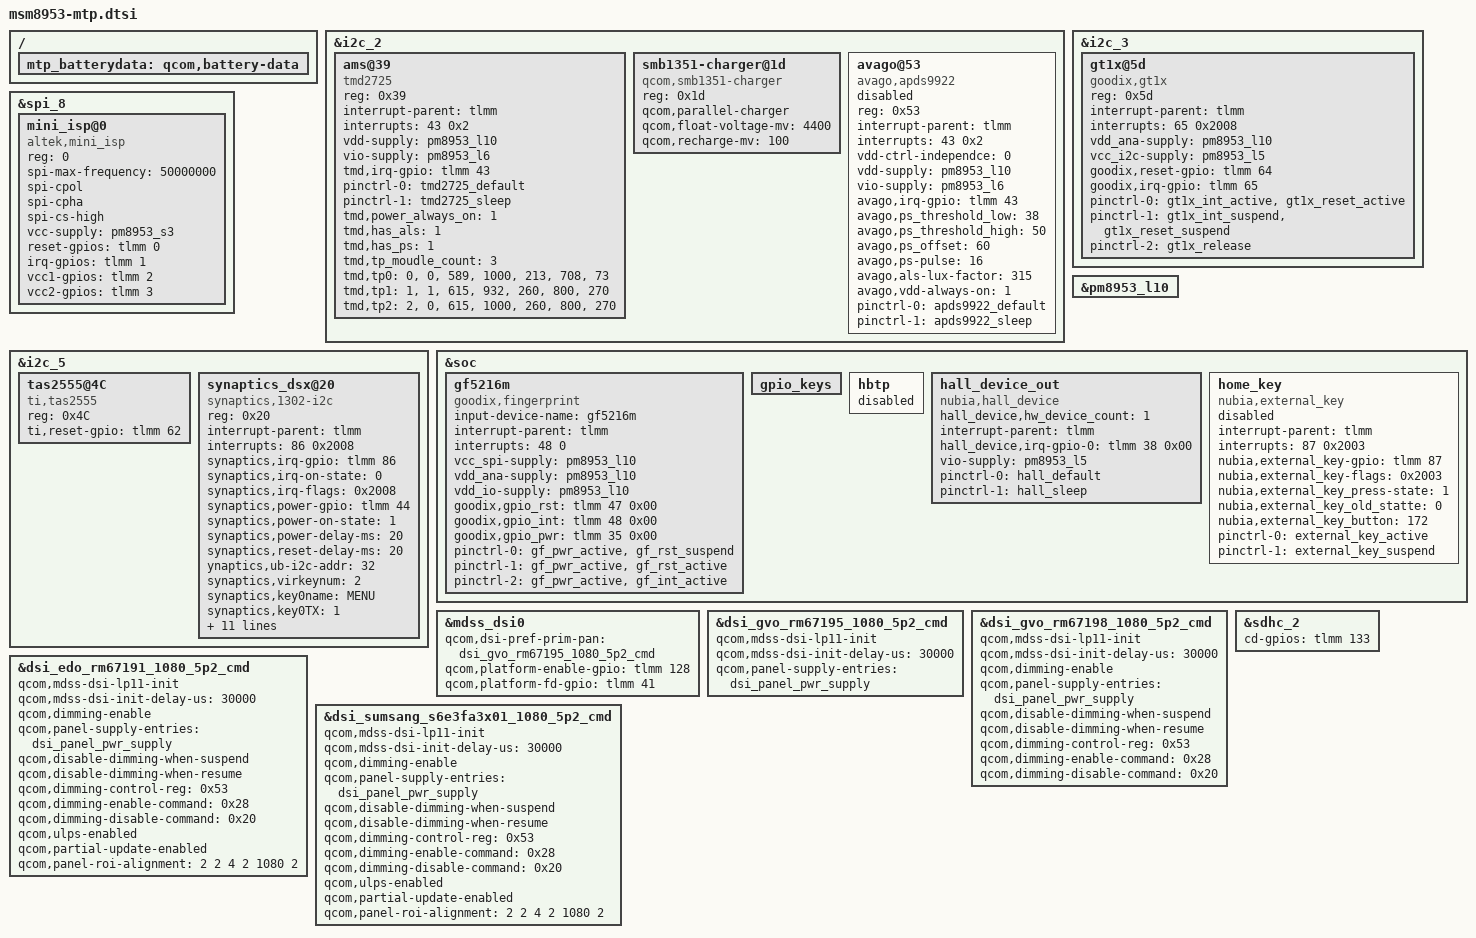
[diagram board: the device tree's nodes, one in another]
/*
 * Copyright (c) 2015-2016, The Linux Foundation. All rights reserved.
 *
 * This program is free software; you can redistribute it and/or modify
 * it under the terms of the GNU General Public License version 2 and
 * only version 2 as published by the Free Software Foundation.
 *
 * This program is distributed in the hope that it will be useful,
 * but WITHOUT ANY WARRANTY; without even the implied warranty of
 * MERCHANTABILITY or FITNESS FOR A PARTICULAR PURPOSE.  See the
 * GNU General Public License for more details.
 */

&i2c_2 {
		ams@39 {
			compatible = "tmd2725";
			reg = <0x39>;
			interrupt-parent = <&tlmm>;
			interrupts = <43 0x2>;
			vdd-supply = <&pm8953_l10>;
			vio-supply = <&pm8953_l6>;
			tmd,irq-gpio = <&tlmm 43 0x2002>;
			pinctrl-names = "tmd2725_default","tmd2725_sleep";
			pinctrl-0 = <&tmd2725_default>;
			pinctrl-1 = <&tmd2725_sleep>;
			tmd,power_always_on = <1>;
			tmd,has_als = <1>;
			tmd,has_ps = <1>;
			tmd,tp_moudle_count = <3>;
			//[module_id] [which_seg] [d_factor] ch0[1] ch1[0] ch0[1] ch1[0]
			tmd,tp0 = "0","0","589","1000","213","708","73";
			//[module_id] [which_seg] [d_factor] ch0[1] ch1[0] ch0[1] ch1[0]
			tmd,tp1 = "1","1","615","932","260","800","270";
			//[module_id] [which_seg] [d_factor] ch0[1] ch1[0] ch0[1] ch1[0]
			tmd,tp2 = "2","0","615","1000","260","800","270";
		};
		smb1351-charger@1d {
			compatible = "qcom,smb1351-charger";
			reg = <0x1d>;
			qcom,parallel-charger;
			qcom,float-voltage-mv = <4400>;
			qcom,recharge-mv = <100>;
		};

		avago@53 {
				status = "disabled";
				compatible = "avago,apds9922";
				reg = <0x53>;
				interrupt-parent = <&tlmm>;
				interrupts = <43 0x2>;
				vdd-ctrl-independce = <0>;
				vdd-supply = <&pm8953_l10>;
				vio-supply = <&pm8953_l6>;
				avago,irq-gpio = <&tlmm 43 0x2002>;
				avago,ps_threshold_low = <38>;
				avago,ps_threshold_high = <50>;
				avago,ps_offset = <60>;
				avago,ps-pulse = <16>;
				avago,als-lux-factor = <315>;
				avago,vdd-always-on = <1>;
				pinctrl-names = "apds9922_default","apds9922_sleep";
				pinctrl-0 = <&apds9922_default>;
				pinctrl-1 = <&apds9922_sleep>;
			};

};
&i2c_3 {
	gt1x@5d {
		compatible = "goodix,gt1x";
		reg = <0x5d>;
		interrupt-parent = <&tlmm>;
		interrupts = <65 0x2008>;
		vdd_ana-supply = <&pm8953_l10>;
//		vdd_io-supply = <&pm8953_l5>;
		vcc_i2c-supply = <&pm8953_l5>;
		goodix,reset-gpio = <&tlmm 64 0x00>;
		goodix,irq-gpio = <&tlmm 65 0x2008>;
		pinctrl-names = "gt1x_pin_active", "gt1x_pin_suspend", "gt1x_pin_release";
		pinctrl-0 = <&gt1x_int_active &gt1x_reset_active>;
		pinctrl-1 = <&gt1x_int_suspend &gt1x_reset_suspend>;
		pinctrl-2 = <&gt1x_release>;
	};

};

//ZTEMT: fengxun added for AL3200 ---start
&spi_8 { /* BLSP2 QUP4 */
	mini_isp@0 {
		compatible = "altek,mini_isp";
		reg = <0>;
		spi-max-frequency = <50000000>;
		spi-cpol;
		spi-cpha;
		spi-cs-high;
		vcc-supply = <&pm8953_s3>;
		reset-gpios = <&tlmm 0 0x00>;
		irq-gpios = <&tlmm 1    0x00>;
		vcc1-gpios = <&tlmm 2 0x00>;
		vcc2-gpios = <&tlmm 3 0x00>;
		status = "ok";
	};
};
//ZTEMT: fengxun added for AL3200 ---end
&i2c_5 { /* BLSP2 QUP1 (NFC) */
       tas2555@4C {
               compatible = "ti,tas2555";
               reg = <0x4C>;
               ti,reset-gpio = <&tlmm 62 0x00>;
       };


	synaptics_dsx@20 {
			compatible = "synaptics,1302-i2c";
			reg = <0x20>;
			interrupt-parent = <&tlmm>;
			interrupts = <86 0x2008 >;
			synaptics,irq-gpio = <&tlmm 86 0x2008>;
			synaptics,irq-on-state = <0>;
			synaptics,irq-flags = <0x2008>; /* IRQF_ONESHOT | IRQF_TRIGGER_LOW */
			synaptics,power-gpio = <&tlmm 44 0x0>;
			synaptics,power-on-state = <1>;
			synaptics,power-delay-ms = <20>;
			synaptics,reset-delay-ms = <20>;
			ynaptics,ub-i2c-addr = <32>;
			synaptics,virkeynum = <2>;                  //根据具体按键数设置，同时模范下面模式添加
			synaptics,key0name  = "MENU";
			synaptics,key0TX = <1>;
			synaptics,key0RX = <1>;
			synaptics,key0minval = <2400>;
			synaptics,key0maxval = <3500>;
			synaptics,key1name = "BACK";
			synaptics,key1TX = <2>;
			synaptics,key1RX = <1>;
			synaptics,key1minval = <2700>;
			synaptics,key1maxval = <4000>;
			synaptics,cap-button-codes = <139 158>;
			pinctrl-names = "synaptics_pin_active", "synaptics_pin_suspend";
			pinctrl-0 = <&synaptics_int_active>;
			pinctrl-1 = <&synaptics_int_suspend>;
		};
	   
	   
};

&pm8953_l10 {
	/delete-property/ regulator-max-microvolt;
};

&soc {
	/* used for fingerprint device as platform device added by nubia start*/
	gf5216m {
		status = "ok";
		compatible = "goodix,fingerprint";
/*goodix origin start*/
		input-device-name = "gf5216m";
		interrupt-parent = <&tlmm>;
		interrupts = <48 0>;
		vcc_spi-supply = <&pm8953_l10>;
		vdd_ana-supply = <&pm8953_l10>;
		vdd_io-supply = <&pm8953_l10>;
		goodix,gpio_rst = <&tlmm 47 0x00>;
		goodix,gpio_int = <&tlmm 48 0x00>;
		goodix,gpio_pwr = <&tlmm 35 0x00>;
		pinctrl-names = "goodixfp_reset_reset", "goodixfp_reset_active", "goodixfp_irq_active";
		pinctrl-0 = <&gf_pwr_active &gf_rst_suspend>;
		pinctrl-1 = <&gf_pwr_active &gf_rst_active>;
		pinctrl-2 = <&gf_pwr_active &gf_int_active>;
/*goodix origin end*/
	};
	/* used for fingerprint device as platform device added by nubia end*/

	gpio_keys {
		/delete-node/ camera_focus;

		/delete-node/ camera_snapshot;
	};

	hbtp {
		status = "disabled";
	};

	hall_device_out {
		compatible = "nubia,hall_device";
		status = "okay";
		hall_device,hw_device_count = <1>;
		interrupt-parent = <&tlmm>;
		hall_device,irq-gpio-0 = <&tlmm 38 0x00>;
		vio-supply = <&pm8953_l5>;
		pinctrl-names = "hall_default","hall_sleep";
		pinctrl-0 = <&hall_default>;
		pinctrl-1 = <&hall_sleep>;
	};


	home_key {
			status = "disabled";
			compatible = "nubia,external_key";
			interrupt-parent = <&tlmm>;
			interrupts = <87 0x2003 >;
			nubia,external_key-gpio = <&tlmm 87 0x0>;
			nubia,external_key-flags = <0x2003>; /* 2003 IRQF_ONESHOT | IRQF_TRIGGER_RISING | IRQF_TRIGGER_RISING*/
			nubia,external_key_press-state = <1>;
			nubia,external_key_old_statte = <0>;
			nubia,external_key_button=<172>;
			pinctrl-names = "external_key_pin_active", "external_key_pin_suspend";
			pinctrl-0 = <&external_key_active>;
			pinctrl-1 = <&external_key_suspend>;
		};
};

&mdss_dsi0 {
	qcom,dsi-pref-prim-pan = <&dsi_gvo_rm67195_1080_5p2_cmd>;
	qcom,platform-enable-gpio = <&tlmm 128 0>;
	qcom,platform-fd-gpio = <&tlmm 41 0>;
};


&dsi_gvo_rm67195_1080_5p2_cmd {
        //qcom,cont-splash-enabled;

    //LP11
    qcom,mdss-dsi-lp11-init;
    qcom,mdss-dsi-init-delay-us = <30000>;

        //Dimming control
        //qcom,dimming-enable;
        qcom,panel-supply-entries = <&dsi_panel_pwr_supply>;
        //qcom,disable-dimming-when-suspend;
        //qcom,disable-dimming-when-resume;
        //qcom,dimming-control-reg         = <0x53>;
        //qcom,dimming-enable-command  = <0x28>;
        //qcom,dimming-disable-command = <0x20>;

        //qcom,ulps-enabled;
        //qcom,partial-update-enabled;
        //qcom,panel-roi-alignment = <2 2 4 2 1080 2>;
};

&dsi_gvo_rm67198_1080_5p2_cmd {
        //qcom,cont-splash-enabled;

    //LP11
    qcom,mdss-dsi-lp11-init;
    qcom,mdss-dsi-init-delay-us = <30000>;

        //Dimming control
        qcom,dimming-enable;
        qcom,panel-supply-entries = <&dsi_panel_pwr_supply>;
        qcom,disable-dimming-when-suspend;
        qcom,disable-dimming-when-resume;
        qcom,dimming-control-reg         = <0x53>;
        qcom,dimming-enable-command  = <0x28>;
        qcom,dimming-disable-command = <0x20>;

        //qcom,ulps-enabled;
       // qcom,partial-update-enabled;
       // qcom,panel-roi-alignment = <2 2 4 2 1080 2>;
};

&dsi_edo_rm67191_1080_5p2_cmd {
        //qcom,cont-splash-enabled;

    //LP11
    qcom,mdss-dsi-lp11-init;
    qcom,mdss-dsi-init-delay-us = <30000>;

        //Dimming control
        qcom,dimming-enable;
        qcom,panel-supply-entries = <&dsi_panel_pwr_supply>;
        qcom,disable-dimming-when-suspend;
        qcom,disable-dimming-when-resume;
        qcom,dimming-control-reg         = <0x53>;
        qcom,dimming-enable-command  = <0x28>;
        qcom,dimming-disable-command = <0x20>;

        qcom,ulps-enabled;
        qcom,partial-update-enabled;
        qcom,panel-roi-alignment = <2 2 4 2 1080 2>;
};

&dsi_sumsang_s6e3fa3x01_1080_5p2_cmd {
        //qcom,cont-splash-enabled;

    //LP11
    qcom,mdss-dsi-lp11-init;
    qcom,mdss-dsi-init-delay-us = <30000>;

        //Dimming control
        qcom,dimming-enable;
        qcom,panel-supply-entries = <&dsi_panel_pwr_supply>;
        qcom,disable-dimming-when-suspend;
        qcom,disable-dimming-when-resume;
        qcom,dimming-control-reg         = <0x53>;
        qcom,dimming-enable-command  = <0x28>;
        qcom,dimming-disable-command = <0x20>;

        qcom,ulps-enabled;
        qcom,partial-update-enabled;
        qcom,panel-roi-alignment = <2 2 4 2 1080 2>;
};



&sdhc_2 {
	cd-gpios = <&tlmm 133 0x0>;
};

/{
	mtp_batterydata: qcom,battery-data {
        /* ZTEMT_CHARGE */
		#include "../batterydata-qrd-sku1-4v4-2800mah.dtsi" 
	};
};

